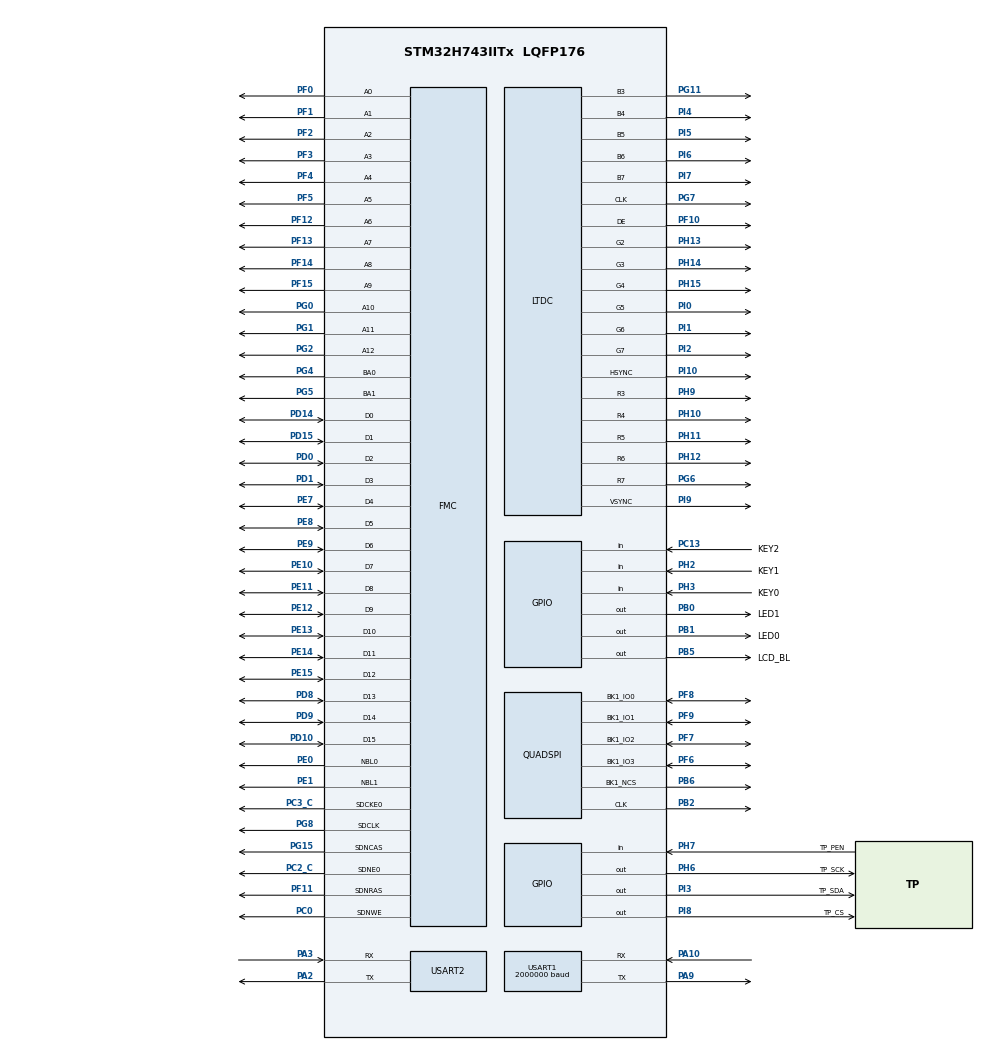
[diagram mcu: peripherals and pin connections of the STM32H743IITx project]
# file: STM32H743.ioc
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DMA2D.ColorMode=DMA2D_OUTPUT_RGB565
FMC.CASLatency1=FMC_SDRAM_CAS_LATENCY_3
FMC.ColumnBitsNumber1=FMC_SDRAM_COLUMN_BITS_NUM_9
FMC.ExitSelfRefreshDelay1=8
FMC.LoadToActiveDelay1=2
FMC.RCDDelay1=2
FMC.RPDelay1=2
FMC.RPDelay2=2
FMC.ReadBurst1=FMC_SDRAM_RBURST_ENABLE
FMC.ReadBurst2=FMC_SDRAM_RBURST_ENABLE
FMC.ReadPipeDelay1=FMC_SDRAM_RPIPE_DELAY_1
FMC.ReadPipeDelay2=FMC_SDRAM_RPIPE_DELAY_1
FMC.RowCycleDelay1=6
FMC.RowCycleDelay2=6
FMC.SDClockPeriod1=FMC_SDRAM_CLOCK_PERIOD_2
FMC.SDClockPeriod2=FMC_SDRAM_CLOCK_PERIOD_2
FMC.SelfRefreshTime1=6
FMC.WriteRecoveryTime1=6
LTDC.ActiveH=600
LTDC.ActiveW=1024
LTDC.Alpha_L0=255
LTDC.FBStartAdress_L0=0xC0000000
LTDC.HBP=140
LTDC.HFP=160
LTDC.HSync=20
LTDC.ImageHeight_L0=600
LTDC.ImageWidth_L0=1024
LTDC.Layers=0
LTDC.PixelFormat_L0=LTDC_PIXEL_FORMAT_RGB565
LTDC.VBP=20
LTDC.VFP=12
LTDC.VSync=3
LTDC.WindowX1_L0=1024
LTDC.WindowY1_L0=600
Mcu.Family=STM32H7
Mcu.Name=STM32H743IITx
Mcu.Package=LQFP176
NVIC.DMA2D_IRQn=true\:0\:0\:false\:false\:true\:true\:true\:true
NVIC.LTDC_IRQn=true\:1\:0\:true\:false\:true\:true\:true\:true
NVIC.PriorityGroup=NVIC_PRIORITYGROUP_4
NVIC.TIM3_IRQn=true\:1\:0\:true\:false\:true\:true\:true\:true
NVIC.USART1_IRQn=true\:1\:0\:true\:false\:true\:true\:true\:true
NVIC.USART2_IRQn=true\:0\:0\:false\:false\:true\:true\:true\:true
PA10.Mode=Asynchronous
PA10.Signal=USART1_RX
PA2.Mode=Asynchronous
PA2.Signal=USART2_TX
PA3.Mode=Asynchronous
PA3.Signal=USART2_RX
PA9.Mode=Asynchronous
PA9.Signal=USART1_TX
PB0.GPIO_Label=LED1
PB0.GPIO_PuPd=GPIO_PULLUP
PB0.GPIO_Speed=GPIO_SPEED_FREQ_HIGH
PB0.PinState=GPIO_PIN_SET
PB0.Signal=GPIO_Output
PB1.GPIO_Label=LED0
PB1.GPIO_PuPd=GPIO_PULLUP
PB1.GPIO_Speed=GPIO_SPEED_FREQ_HIGH
PB1.PinState=GPIO_PIN_SET
PB1.Signal=GPIO_Output
PB2.GPIO_Speed=GPIO_SPEED_FREQ_VERY_HIGH
PB2.Mode=Single Bank 1
PB2.Signal=QUADSPI_CLK
PB5.GPIO_Label=LCD_BL
PB5.PinState=GPIO_PIN_SET
PB5.Signal=GPIO_Output
PB6.GPIO_Speed=GPIO_SPEED_FREQ_VERY_HIGH
PB6.Mode=Single Bank 1
PB6.Signal=QUADSPI_BK1_NCS
PC0.Signal=FMC_SDNWE
PC13.GPIO_Label=KEY2
PC13.GPIO_PuPd=GPIO_PULLUP
PC13.Signal=GPIO_Input
PC14-OSC32_IN\ (OSC32_IN).Mode=LSE-External-Oscillator
PC14-OSC32_IN\ (OSC32_IN).Signal=RCC_OSC32_IN
PC15-OSC32_OUT\ (OSC32_OUT).Mode=LSE-External-Oscillator
PC15-OSC32_OUT\ (OSC32_OUT).Signal=RCC_OSC32_OUT
PC2_C.Mode=SdramChipSelect1_1
PC2_C.Signal=FMC_SDNE0
PC3_C.Mode=SdramChipSelect1_1
PC3_C.Signal=FMC_SDCKE0
PD0.Signal=FMC_D2_DA2
PD1.Signal=FMC_D3_DA3
PD10.Signal=FMC_D15_DA15
PD14.Signal=FMC_D0_DA0
PD15.Signal=FMC_D1_DA1
PD8.Signal=FMC_D13_DA13
PD9.Signal=FMC_D14_DA14
PE0.Signal=FMC_NBL0
PE1.Signal=FMC_NBL1
PE10.Signal=FMC_D7_DA7
PE11.Signal=FMC_D8_DA8
PE12.Signal=FMC_D9_DA9
PE13.Signal=FMC_D10_DA10
PE14.Signal=FMC_D11_DA11
PE15.Signal=FMC_D12_DA12
PE7.Signal=FMC_D4_DA4
PE8.Signal=FMC_D5_DA5
PE9.Signal=FMC_D6_DA6
PF0.Signal=FMC_A0
PF1.Signal=FMC_A1
PF10.GPIO_Speed=GPIO_SPEED_FREQ_VERY_HIGH
PF10.Mode=RGB565
PF10.Signal=LTDC_DE
PF11.Signal=FMC_SDNRAS
PF12.Signal=FMC_A6
PF13.Signal=FMC_A7
PF14.Signal=FMC_A8
PF15.Signal=FMC_A9
PF2.Signal=FMC_A2
PF3.Signal=FMC_A3
PF4.Signal=FMC_A4
PF5.Signal=FMC_A5
PF6.GPIO_Speed=GPIO_SPEED_FREQ_VERY_HIGH
PF6.Mode=Single Bank 1
PF6.Signal=QUADSPI_BK1_IO3
PF7.GPIO_Speed=GPIO_SPEED_FREQ_VERY_HIGH
PF7.Mode=Single Bank 1
PF7.Signal=QUADSPI_BK1_IO2
PF8.GPIO_Speed=GPIO_SPEED_FREQ_VERY_HIGH
PF8.Mode=Single Bank 1
PF8.Signal=QUADSPI_BK1_IO0
PF9.GPIO_Speed=GPIO_SPEED_FREQ_VERY_HIGH
PF9.Mode=Single Bank 1
PF9.Signal=QUADSPI_BK1_IO1
PG0.Signal=FMC_A10
PG1.Signal=FMC_A11
PG11.GPIO_Speed=GPIO_SPEED_FREQ_VERY_HIGH
PG11.Mode=RGB565
PG11.Signal=LTDC_B3
PG15.Signal=FMC_SDNCAS
PG2.Signal=FMC_A12
PG4.Signal=FMC_A14_BA0
PG5.Signal=FMC_A15_BA1
PG6.GPIO_Speed=GPIO_SPEED_FREQ_VERY_HIGH
PG6.Mode=RGB565
PG6.Signal=LTDC_R7
PG7.GPIO_Speed=GPIO_SPEED_FREQ_VERY_HIGH
PG7.Mode=RGB565
PG7.Signal=LTDC_CLK
PG8.Signal=FMC_SDCLK
PH0-OSC_IN\ (PH0).Mode=HSE-External-Oscillator
PH0-OSC_IN\ (PH0).Signal=RCC_OSC_IN
PH1-OSC_OUT\ (PH1).Mode=HSE-External-Oscillator
PH1-OSC_OUT\ (PH1).Signal=RCC_OSC_OUT
PH10.GPIO_Speed=GPIO_SPEED_FREQ_VERY_HIGH
PH10.Mode=RGB565
PH10.Signal=LTDC_R4
PH11.GPIO_Speed=GPIO_SPEED_FREQ_VERY_HIGH
PH11.Mode=RGB565
PH11.Signal=LTDC_R5
PH12.GPIO_Speed=GPIO_SPEED_FREQ_VERY_HIGH
PH12.Mode=RGB565
PH12.Signal=LTDC_R6
PH13.GPIO_Speed=GPIO_SPEED_FREQ_VERY_HIGH
PH13.Mode=RGB565
PH13.Signal=LTDC_G2
PH14.GPIO_Speed=GPIO_SPEED_FREQ_VERY_HIGH
PH14.Mode=RGB565
PH14.Signal=LTDC_G3
PH15.GPIO_Speed=GPIO_SPEED_FREQ_VERY_HIGH
PH15.Mode=RGB565
PH15.Signal=LTDC_G4
PH2.GPIO_Label=KEY1
PH2.GPIO_PuPd=GPIO_PULLUP
PH2.Signal=GPIO_Input
PH3.GPIO_Label=KEY0
PH3.GPIO_PuPd=GPIO_PULLUP
PH3.Signal=GPIO_Input
PH6.GPIO_Label=TP_SCK
PH6.GPIO_PuPd=GPIO_PULLUP
PH6.GPIO_Speed=GPIO_SPEED_FREQ_HIGH
PH6.PinState=GPIO_PIN_SET
PH6.Signal=GPIO_Output
PH7.GPIO_Label=TP_PEN
PH7.Signal=GPIO_Input
PH9.GPIO_Speed=GPIO_SPEED_FREQ_VERY_HIGH
PH9.Mode=RGB565
PH9.Signal=LTDC_R3
PI0.GPIO_Speed=GPIO_SPEED_FREQ_VERY_HIGH
PI0.Mode=RGB565
PI0.Signal=LTDC_G5
PI1.GPIO_Speed=GPIO_SPEED_FREQ_VERY_HIGH
PI1.Mode=RGB565
PI1.Signal=LTDC_G6
PI10.GPIO_Speed=GPIO_SPEED_FREQ_VERY_HIGH
PI10.Mode=RGB565
PI10.Signal=LTDC_HSYNC
PI2.GPIO_Speed=GPIO_SPEED_FREQ_VERY_HIGH
PI2.Mode=RGB565
PI2.Signal=LTDC_G7
PI3.GPIO_Label=TP_SDA
PI3.GPIO_ModeDefaultOutputPP=GPIO_MODE_OUTPUT_OD
PI3.GPIO_PuPd=GPIO_PULLUP
PI3.PinState=GPIO_PIN_SET
PI3.Signal=GPIO_Output
PI4.GPIO_Speed=GPIO_SPEED_FREQ_VERY_HIGH
PI4.Mode=RGB565
PI4.Signal=LTDC_B4
PI5.GPIO_Speed=GPIO_SPEED_FREQ_VERY_HIGH
PI5.Mode=RGB565
PI5.Signal=LTDC_B5
PI6.GPIO_Speed=GPIO_SPEED_FREQ_VERY_HIGH
PI6.Mode=RGB565
PI6.Signal=LTDC_B6
PI7.GPIO_Speed=GPIO_SPEED_FREQ_VERY_HIGH
PI7.Mode=RGB565
PI7.Signal=LTDC_B7
PI8.GPIO_Label=TP_CS
PI8.GPIO_PuPd=GPIO_PULLUP
PI8.GPIO_Speed=GPIO_SPEED_FREQ_LOW
PI8.PinState=GPIO_PIN_SET
PI8.Signal=GPIO_Output
PI9.GPIO_Speed=GPIO_SPEED_FREQ_VERY_HIGH
PI9.Mode=RGB565
PI9.Signal=LTDC_VSYNC
ProjectManager.HeapSize=0x200
ProjectManager.StackSize=0x400
ProjectManager.TargetToolchain=STM32CubeIDE
QUADSPI.ChipSelectHighTime=QSPI_CS_HIGH_TIME_5_CYCLE
QUADSPI.ClockPrescaler=1
QUADSPI.FifoThreshold=4
QUADSPI.FlashSize=24
QUADSPI.SampleShifting=QSPI_SAMPLE_SHIFTING_HALFCYCLE
RCC.ADCFreq_Value=50390625
RCC.APB1Freq_Value=100000000
RCC.APB2Freq_Value=100000000
RCC.APB3Freq_Value=100000000
RCC.APB4Freq_Value=100000000
RCC.CortexFreq_Value=400000000
RCC.D1PPRE=RCC_APB3_DIV2
RCC.D2PPRE1=RCC_APB1_DIV2
RCC.D2PPRE2=RCC_APB2_DIV2
RCC.D3PPRE=RCC_APB4_DIV2
RCC.DIVM1=2
RCC.DIVN1=64
RCC.DIVN3=192
RCC.DIVR3=3
RCC.HCLKFreq_Value=200000000
RCC.HPRE=RCC_HCLK_DIV2
RCC.PLL2FRACN=0
RCC.PLL3FRACN=0
RCC.PLLFRACN=0
RCC.PLLSourceVirtual=RCC_PLLSOURCE_HSE
RCC.SYSCLKFreq_VALUE=400000000
RCC.SYSCLKSource=RCC_SYSCLKSOURCE_PLLCLK
RCC.USBFreq_Value=400000000
SH.FMC_A0.0=FMC_A0,13b-sda1
SH.FMC_A1.0=FMC_A1,13b-sda1
SH.FMC_A10.0=FMC_A10,13b-sda1
SH.FMC_A11.0=FMC_A11,13b-sda1
SH.FMC_A12.0=FMC_A12,13b-sda1
SH.FMC_A14_BA0.0=FMC_BA0,FourSdramBanks1
SH.FMC_A15_BA1.0=FMC_BA1,FourSdramBanks1
SH.FMC_A2.0=FMC_A2,13b-sda1
SH.FMC_A3.0=FMC_A3,13b-sda1
SH.FMC_A4.0=FMC_A4,13b-sda1
SH.FMC_A5.0=FMC_A5,13b-sda1
SH.FMC_A6.0=FMC_A6,13b-sda1
SH.FMC_A7.0=FMC_A7,13b-sda1
SH.FMC_A8.0=FMC_A8,13b-sda1
SH.FMC_A9.0=FMC_A9,13b-sda1
SH.FMC_D0_DA0.0=FMC_D0,sd-16b-d1
SH.FMC_D10_DA10.0=FMC_D10,sd-16b-d1
SH.FMC_D11_DA11.0=FMC_D11,sd-16b-d1
SH.FMC_D12_DA12.0=FMC_D12,sd-16b-d1
SH.FMC_D13_DA13.0=FMC_D13,sd-16b-d1
SH.FMC_D14_DA14.0=FMC_D14,sd-16b-d1
SH.FMC_D15_DA15.0=FMC_D15,sd-16b-d1
SH.FMC_D1_DA1.0=FMC_D1,sd-16b-d1
SH.FMC_D2_DA2.0=FMC_D2,sd-16b-d1
SH.FMC_D3_DA3.0=FMC_D3,sd-16b-d1
SH.FMC_D4_DA4.0=FMC_D4,sd-16b-d1
SH.FMC_D5_DA5.0=FMC_D5,sd-16b-d1
SH.FMC_D6_DA6.0=FMC_D6,sd-16b-d1
SH.FMC_D7_DA7.0=FMC_D7,sd-16b-d1
SH.FMC_D8_DA8.0=FMC_D8,sd-16b-d1
SH.FMC_D9_DA9.0=FMC_D9,sd-16b-d1
SH.FMC_NBL0.0=FMC_NBL0,Sd2ByteEnable1
SH.FMC_NBL1.0=FMC_NBL1,Sd2ByteEnable1
SH.FMC_SDCLK.0=FMC_SDCLK,13b-sda1
SH.FMC_SDNCAS.0=FMC_SDNCAS,13b-sda1
SH.FMC_SDNRAS.0=FMC_SDNRAS,13b-sda1
SH.FMC_SDNWE.0=FMC_SDNWE,13b-sda1
USART1.BaudRate=2000000
USART1.VirtualMode-Asynchronous=VM_ASYNC
USART2.VirtualMode-Asynchronous=VM_ASYNC
VP_DMA2D_VS_DMA2D.Mode=DMA2D_Activate
VP_TIM3_VS_ClockSourceINT.Mode=Internal
board=custom

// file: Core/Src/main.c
/* USER CODE BEGIN Header */
/**
  ******************************************************************************
  * @file           : main.c
  * @brief          : Main program body
  ******************************************************************************
  * @attention
  *
  * Copyright (c) 2023 STMicroelectronics.
  * All rights reserved.
  *
  * This software is licensed under terms that can be found in the LICENSE file
  * in the root directory of this software component.
  * If no LICENSE file comes with this software, it is provided AS-IS.
  *
  ******************************************************************************
  */
/* USER CODE END Header */
#include "main.h"

/* USER CODE BEGIN Includes */
#include "sdram.h"
#include "stdio.h"
#include "user_uart.h"
#include "TFTLCD.h"
#include "QSPI_flash.h"
#include "key_led.h"
#include "spi_flash_data.h"
#include "user_delay.h"
#include "touch.h"
#include "tft_lcd_draw.h"

/* USER CODE END Includes */

DMA2D_HandleTypeDef hdma2d;

LTDC_HandleTypeDef hltdc;

QSPI_HandleTypeDef hqspi;

TIM_HandleTypeDef htim3;

UART_HandleTypeDef huart1;
UART_HandleTypeDef huart2;

SDRAM_HandleTypeDef hsdram1;

/* USER CODE BEGIN PV */
uint16_t test_spi_id;
/* USER CODE END PV */

void SystemClock_Config(void);
static void MX_GPIO_Init(void);
static void MX_TIM3_Init(void);
static void MX_USART1_UART_Init(void);
static void MX_USART2_UART_Init(void);
static void MX_FMC_Init(void);
static void MX_LTDC_Init(void);
static void MX_DMA2D_Init(void);
static void MX_QUADSPI_Init(void);

int main(void)
{

  /* MCU Configuration--------------------------------------------------------*/

  /* Reset of all peripherals, Initializes the Flash interface and the Systick. */
  HAL_Init();

  /* Configure the system clock */
  SystemClock_Config();

  /* Initialize all configured peripherals */
  MX_GPIO_Init();
  MX_TIM3_Init();
  MX_USART1_UART_Init();
  MX_USART2_UART_Init();
  MX_FMC_Init();
  MX_LTDC_Init();
  MX_DMA2D_Init();
  MX_QUADSPI_Init();
  /* USER CODE BEGIN 2 */
  log_com_uart_init();
  user_delay_init(400);
//  printf("STM32H743 SDRAM Test \r\n");

  SDRAM_Init();

//  printf("SDRAM  Init success\r\n");
//
//  if (bsp_TestExtSDRAM() == 0) {
//      printf("SDRAM Test success\r\n");
//  } else {
//      printf("SDRAM Test fail\r\n");
//  }

  W25QXX_Init();
  touch_init();
  TFTLCD_clear(WHITE);
  /* USER CODE END 2 */

  /* Infinite loop */
  while (1)
  {

    /* USER CODE BEGIN 3 */
//	  printf("STM32F767 SDRAM Test \r\n");
//	  HAL_Delay(1000);
//	  test_tft_lcd();
//	  test_lcd_show_picture();
//	  test_spi_id = W25QXX_ReadID();
//	  printf("test_spi_id = %x \r\n",test_spi_id);
//	  HAL_Delay(1000);
//	  test_spi_flash();
//	  test_picture_show();
//	  TFTLCD_test();
//	  touch_test();
	  tft_lcd_draw();
  }
  /* USER CODE END 3 */
}

void SystemClock_Config(void)
{
  RCC_OscInitTypeDef RCC_OscInitStruct = {0};
  RCC_ClkInitTypeDef RCC_ClkInitStruct = {0};

  /** Supply configuration update enable
  */
  HAL_PWREx_ConfigSupply(PWR_LDO_SUPPLY);

  /** Configure the main internal regulator output voltage
  */
  __HAL_PWR_VOLTAGESCALING_CONFIG(PWR_REGULATOR_VOLTAGE_SCALE1);

  while(!__HAL_PWR_GET_FLAG(PWR_FLAG_VOSRDY)) {}

  /** Initializes the RCC Oscillators according to the specified parameters
  * in the RCC_OscInitTypeDef structure.
  */
  RCC_OscInitStruct.OscillatorType = RCC_OSCILLATORTYPE_HSE;
  RCC_OscInitStruct.HSEState = RCC_HSE_ON;
  RCC_OscInitStruct.PLL.PLLState = RCC_PLL_ON;
  RCC_OscInitStruct.PLL.PLLSource = RCC_PLLSOURCE_HSE;
  RCC_OscInitStruct.PLL.PLLM = 2;
  RCC_OscInitStruct.PLL.PLLN = 64;
  RCC_OscInitStruct.PLL.PLLP = 2;
  RCC_OscInitStruct.PLL.PLLQ = 2;
  RCC_OscInitStruct.PLL.PLLR = 2;
  RCC_OscInitStruct.PLL.PLLRGE = RCC_PLL1VCIRANGE_3;
  RCC_OscInitStruct.PLL.PLLVCOSEL = RCC_PLL1VCOWIDE;
  RCC_OscInitStruct.PLL.PLLFRACN = 0;
  if (HAL_RCC_OscConfig(&RCC_OscInitStruct) != HAL_OK)
  {
    Error_Handler();
  }

  /** Initializes the CPU, AHB and APB buses clocks
  */
  RCC_ClkInitStruct.ClockType = RCC_CLOCKTYPE_HCLK|RCC_CLOCKTYPE_SYSCLK
                              |RCC_CLOCKTYPE_PCLK1|RCC_CLOCKTYPE_PCLK2
                              |RCC_CLOCKTYPE_D3PCLK1|RCC_CLOCKTYPE_D1PCLK1;
  RCC_ClkInitStruct.SYSCLKSource = RCC_SYSCLKSOURCE_PLLCLK;
  RCC_ClkInitStruct.SYSCLKDivider = RCC_SYSCLK_DIV1;
  RCC_ClkInitStruct.AHBCLKDivider = RCC_HCLK_DIV2;
  RCC_ClkInitStruct.APB3CLKDivider = RCC_APB3_DIV2;
  RCC_ClkInitStruct.APB1CLKDivider = RCC_APB1_DIV2;
  RCC_ClkInitStruct.APB2CLKDivider = RCC_APB2_DIV2;
  RCC_ClkInitStruct.APB4CLKDivider = RCC_APB4_DIV2;

  if (HAL_RCC_ClockConfig(&RCC_ClkInitStruct, FLASH_LATENCY_2) != HAL_OK)
  {
    Error_Handler();
  }
}

static void MX_DMA2D_Init(void)
{

  hdma2d.Instance = DMA2D;
  hdma2d.Init.Mode = DMA2D_M2M;
  hdma2d.Init.ColorMode = DMA2D_OUTPUT_RGB565;
  hdma2d.Init.OutputOffset = 0;
  hdma2d.LayerCfg[1].InputOffset = 0;
  hdma2d.LayerCfg[1].InputColorMode = DMA2D_INPUT_RGB565;
  hdma2d.LayerCfg[1].AlphaMode = DMA2D_NO_MODIF_ALPHA;
  hdma2d.LayerCfg[1].InputAlpha = 0;
  hdma2d.LayerCfg[1].AlphaInverted = DMA2D_REGULAR_ALPHA;
  hdma2d.LayerCfg[1].RedBlueSwap = DMA2D_RB_REGULAR;
  hdma2d.LayerCfg[1].ChromaSubSampling = DMA2D_NO_CSS;
  if (HAL_DMA2D_Init(&hdma2d) != HAL_OK)
  {
    Error_Handler();
  }
  if (HAL_DMA2D_ConfigLayer(&hdma2d, 1) != HAL_OK)
  {
    Error_Handler();
  }

}

static void MX_LTDC_Init(void)
{

  LTDC_LayerCfgTypeDef pLayerCfg = {0};

  hltdc.Instance = LTDC;
  hltdc.Init.HSPolarity = LTDC_HSPOLARITY_AL;
  hltdc.Init.VSPolarity = LTDC_VSPOLARITY_AL;
  hltdc.Init.DEPolarity = LTDC_DEPOLARITY_AL;
  hltdc.Init.PCPolarity = LTDC_PCPOLARITY_IPC;
  hltdc.Init.HorizontalSync = 19;
  hltdc.Init.VerticalSync = 2;
  hltdc.Init.AccumulatedHBP = 159;
  hltdc.Init.AccumulatedVBP = 22;
  hltdc.Init.AccumulatedActiveW = 1183;
  hltdc.Init.AccumulatedActiveH = 622;
  hltdc.Init.TotalWidth = 1343;
  hltdc.Init.TotalHeigh = 634;
  hltdc.Init.Backcolor.Blue = 0;
  hltdc.Init.Backcolor.Green = 0;
  hltdc.Init.Backcolor.Red = 0;
  if (HAL_LTDC_Init(&hltdc) != HAL_OK)
  {
    Error_Handler();
  }
  pLayerCfg.WindowX0 = 0;
  pLayerCfg.WindowX1 = 1024;
  pLayerCfg.WindowY0 = 0;
  pLayerCfg.WindowY1 = 600;
  pLayerCfg.PixelFormat = LTDC_PIXEL_FORMAT_RGB565;
  pLayerCfg.Alpha = 255;
  pLayerCfg.Alpha0 = 0;
  pLayerCfg.BlendingFactor1 = LTDC_BLENDING_FACTOR1_CA;
  pLayerCfg.BlendingFactor2 = LTDC_BLENDING_FACTOR2_CA;
  pLayerCfg.FBStartAdress = 0xC0000000;
  pLayerCfg.ImageWidth = 1024;
  pLayerCfg.ImageHeight = 600;
  pLayerCfg.Backcolor.Blue = 0;
  pLayerCfg.Backcolor.Green = 0;
  pLayerCfg.Backcolor.Red = 0;
  if (HAL_LTDC_ConfigLayer(&hltdc, &pLayerCfg, 0) != HAL_OK)
  {
    Error_Handler();
  }

}

static void MX_QUADSPI_Init(void)
{

  /* QUADSPI parameter configuration*/
  hqspi.Instance = QUADSPI;
  hqspi.Init.ClockPrescaler = 1;
  hqspi.Init.FifoThreshold = 4;
  hqspi.Init.SampleShifting = QSPI_SAMPLE_SHIFTING_HALFCYCLE;
  hqspi.Init.FlashSize = 24;
  hqspi.Init.ChipSelectHighTime = QSPI_CS_HIGH_TIME_5_CYCLE;
  hqspi.Init.ClockMode = QSPI_CLOCK_MODE_0;
  hqspi.Init.FlashID = QSPI_FLASH_ID_1;
  hqspi.Init.DualFlash = QSPI_DUALFLASH_DISABLE;
  if (HAL_QSPI_Init(&hqspi) != HAL_OK)
  {
    Error_Handler();
  }

}

static void MX_TIM3_Init(void)
{

  TIM_ClockConfigTypeDef sClockSourceConfig = {0};
  TIM_MasterConfigTypeDef sMasterConfig = {0};

  htim3.Instance = TIM3;
  htim3.Init.Prescaler = 0;
  htim3.Init.CounterMode = TIM_COUNTERMODE_UP;
  htim3.Init.Period = 65535;
  htim3.Init.ClockDivision = TIM_CLOCKDIVISION_DIV1;
  htim3.Init.AutoReloadPreload = TIM_AUTORELOAD_PRELOAD_DISABLE;
  if (HAL_TIM_Base_Init(&htim3) != HAL_OK)
  {
    Error_Handler();
  }
  sClockSourceConfig.ClockSource = TIM_CLOCKSOURCE_INTERNAL;
  if (HAL_TIM_ConfigClockSource(&htim3, &sClockSourceConfig) != HAL_OK)
  {
    Error_Handler();
  }
  sMasterConfig.MasterOutputTrigger = TIM_TRGO_RESET;
  sMasterConfig.MasterSlaveMode = TIM_MASTERSLAVEMODE_DISABLE;
  if (HAL_TIMEx_MasterConfigSynchronization(&htim3, &sMasterConfig) != HAL_OK)
  {
    Error_Handler();
  }

}

static void MX_USART1_UART_Init(void)
{

  huart1.Instance = USART1;
  huart1.Init.BaudRate = 2000000;
  huart1.Init.WordLength = UART_WORDLENGTH_8B;
  huart1.Init.StopBits = UART_STOPBITS_1;
  huart1.Init.Parity = UART_PARITY_NONE;
  huart1.Init.Mode = UART_MODE_TX_RX;
  huart1.Init.HwFlowCtl = UART_HWCONTROL_NONE;
  huart1.Init.OverSampling = UART_OVERSAMPLING_16;
  huart1.Init.OneBitSampling = UART_ONE_BIT_SAMPLE_DISABLE;
  huart1.Init.ClockPrescaler = UART_PRESCALER_DIV1;
  huart1.AdvancedInit.AdvFeatureInit = UART_ADVFEATURE_NO_INIT;
  if (HAL_UART_Init(&huart1) != HAL_OK)
  {
    Error_Handler();
  }
  if (HAL_UARTEx_SetTxFifoThreshold(&huart1, UART_TXFIFO_THRESHOLD_1_8) != HAL_OK)
  {
    Error_Handler();
  }
  if (HAL_UARTEx_SetRxFifoThreshold(&huart1, UART_RXFIFO_THRESHOLD_1_8) != HAL_OK)
  {
    Error_Handler();
  }
  if (HAL_UARTEx_DisableFifoMode(&huart1) != HAL_OK)
  {
    Error_Handler();
  }

}

static void MX_USART2_UART_Init(void)
{

  huart2.Instance = USART2;
  huart2.Init.BaudRate = 115200;
  huart2.Init.WordLength = UART_WORDLENGTH_8B;
  huart2.Init.StopBits = UART_STOPBITS_1;
  huart2.Init.Parity = UART_PARITY_NONE;
  huart2.Init.Mode = UART_MODE_TX_RX;
  huart2.Init.HwFlowCtl = UART_HWCONTROL_NONE;
  huart2.Init.OverSampling = UART_OVERSAMPLING_16;
  huart2.Init.OneBitSampling = UART_ONE_BIT_SAMPLE_DISABLE;
  huart2.Init.ClockPrescaler = UART_PRESCALER_DIV1;
  huart2.AdvancedInit.AdvFeatureInit = UART_ADVFEATURE_NO_INIT;
  if (HAL_UART_Init(&huart2) != HAL_OK)
  {
    Error_Handler();
  }
  if (HAL_UARTEx_SetTxFifoThreshold(&huart2, UART_TXFIFO_THRESHOLD_1_8) != HAL_OK)
  {
    Error_Handler();
  }
  if (HAL_UARTEx_SetRxFifoThreshold(&huart2, UART_RXFIFO_THRESHOLD_1_8) != HAL_OK)
  {
    Error_Handler();
  }
  if (HAL_UARTEx_DisableFifoMode(&huart2) != HAL_OK)
  {
    Error_Handler();
  }

}

/* FMC initialization function */
static void MX_FMC_Init(void)
{

  FMC_SDRAM_TimingTypeDef SdramTiming = {0};

  /** Perform the SDRAM1 memory initialization sequence
  */
  hsdram1.Instance = FMC_SDRAM_DEVICE;
  /* hsdram1.Init */
  hsdram1.Init.SDBank = FMC_SDRAM_BANK1;
  hsdram1.Init.ColumnBitsNumber = FMC_SDRAM_COLUMN_BITS_NUM_9;
  hsdram1.Init.RowBitsNumber = FMC_SDRAM_ROW_BITS_NUM_13;
  hsdram1.Init.MemoryDataWidth = FMC_SDRAM_MEM_BUS_WIDTH_16;
  hsdram1.Init.InternalBankNumber = FMC_SDRAM_INTERN_BANKS_NUM_4;
  hsdram1.Init.CASLatency = FMC_SDRAM_CAS_LATENCY_3;
  hsdram1.Init.WriteProtection = FMC_SDRAM_WRITE_PROTECTION_DISABLE;
  hsdram1.Init.SDClockPeriod = FMC_SDRAM_CLOCK_PERIOD_2;
  hsdram1.Init.ReadBurst = FMC_SDRAM_RBURST_ENABLE;
  hsdram1.Init.ReadPipeDelay = FMC_SDRAM_RPIPE_DELAY_1;
  /* SdramTiming */
  SdramTiming.LoadToActiveDelay = 2;
  SdramTiming.ExitSelfRefreshDelay = 8;
  SdramTiming.SelfRefreshTime = 6;
  SdramTiming.RowCycleDelay = 6;
  SdramTiming.WriteRecoveryTime = 6;
  SdramTiming.RPDelay = 2;
  SdramTiming.RCDDelay = 2;

  if (HAL_SDRAM_Init(&hsdram1, &SdramTiming) != HAL_OK)
  {
    Error_Handler( );
  }

}

static void MX_GPIO_Init(void)
{
  GPIO_InitTypeDef GPIO_InitStruct = {0};

  /* GPIO Ports Clock Enable */
  __HAL_RCC_GPIOI_CLK_ENABLE();
  __HAL_RCC_GPIOC_CLK_ENABLE();
  __HAL_RCC_GPIOF_CLK_ENABLE();
  __HAL_RCC_GPIOH_CLK_ENABLE();
  __HAL_RCC_GPIOA_CLK_ENABLE();
  __HAL_RCC_GPIOB_CLK_ENABLE();
  __HAL_RCC_GPIOG_CLK_ENABLE();
  __HAL_RCC_GPIOE_CLK_ENABLE();
  __HAL_RCC_GPIOD_CLK_ENABLE();

  /*Configure GPIO pin Output Level */
  HAL_GPIO_WritePin(GPIOI, TP_CS_Pin|TP_SDA_Pin, GPIO_PIN_SET);

  /*Configure GPIO pin Output Level */
  HAL_GPIO_WritePin(GPIOB, LED1_Pin|LED0_Pin|LCD_BL_Pin, GPIO_PIN_SET);

  /*Configure GPIO pin Output Level */
  HAL_GPIO_WritePin(TP_SCK_GPIO_Port, TP_SCK_Pin, GPIO_PIN_SET);

  /*Configure GPIO pin : TP_CS_Pin */
  GPIO_InitStruct.Pin = TP_CS_Pin;
  GPIO_InitStruct.Mode = GPIO_MODE_OUTPUT_PP;
  GPIO_InitStruct.Pull = GPIO_PULLUP;
  GPIO_InitStruct.Speed = GPIO_SPEED_FREQ_LOW;
  HAL_GPIO_Init(TP_CS_GPIO_Port, &GPIO_InitStruct);

  /*Configure GPIO pin : KEY2_Pin */
  GPIO_InitStruct.Pin = KEY2_Pin;
  GPIO_InitStruct.Mode = GPIO_MODE_INPUT;
  GPIO_InitStruct.Pull = GPIO_PULLUP;
  HAL_GPIO_Init(KEY2_GPIO_Port, &GPIO_InitStruct);

  /*Configure GPIO pins : KEY1_Pin KEY0_Pin */
  GPIO_InitStruct.Pin = KEY1_Pin|KEY0_Pin;
  GPIO_InitStruct.Mode = GPIO_MODE_INPUT;
  GPIO_InitStruct.Pull = GPIO_PULLUP;
  HAL_GPIO_Init(GPIOH, &GPIO_InitStruct);

  /*Configure GPIO pins : LED1_Pin LED0_Pin */
  GPIO_InitStruct.Pin = LED1_Pin|LED0_Pin;
  GPIO_InitStruct.Mode = GPIO_MODE_OUTPUT_PP;
  GPIO_InitStruct.Pull = GPIO_PULLUP;
  GPIO_InitStruct.Speed = GPIO_SPEED_FREQ_HIGH;
  HAL_GPIO_Init(GPIOB, &GPIO_InitStruct);

  /*Configure GPIO pin : TP_SCK_Pin */
  GPIO_InitStruct.Pin = TP_SCK_Pin;
  GPIO_InitStruct.Mode = GPIO_MODE_OUTPUT_PP;
  GPIO_InitStruct.Pull = GPIO_PULLUP;
  GPIO_InitStruct.Speed = GPIO_SPEED_FREQ_HIGH;
  HAL_GPIO_Init(TP_SCK_GPIO_Port, &GPIO_InitStruct);

  /*Configure GPIO pin : TP_PEN_Pin */
  GPIO_InitStruct.Pin = TP_PEN_Pin;
  GPIO_InitStruct.Mode = GPIO_MODE_INPUT;
  GPIO_InitStruct.Pull = GPIO_NOPULL;
  HAL_GPIO_Init(TP_PEN_GPIO_Port, &GPIO_InitStruct);

  /*Configure GPIO pin : TP_SDA_Pin */
  GPIO_InitStruct.Pin = TP_SDA_Pin;
  GPIO_InitStruct.Mode = GPIO_MODE_OUTPUT_OD;
  GPIO_InitStruct.Pull = GPIO_PULLUP;
  GPIO_InitStruct.Speed = GPIO_SPEED_FREQ_LOW;
  HAL_GPIO_Init(TP_SDA_GPIO_Port, &GPIO_InitStruct);

  /*Configure GPIO pin : LCD_BL_Pin */
  GPIO_InitStruct.Pin = LCD_BL_Pin;
  GPIO_InitStruct.Mode = GPIO_MODE_OUTPUT_PP;
  GPIO_InitStruct.Pull = GPIO_NOPULL;
  GPIO_InitStruct.Speed = GPIO_SPEED_FREQ_LOW;
  HAL_GPIO_Init(LCD_BL_GPIO_Port, &GPIO_InitStruct);

}

void Error_Handler(void)
{
  __disable_irq();
  while (1)
  {
  }
}
